# S6E1A1 register map
File version: 1.2
CPU: 
Registers are 32-bit, read-write, reset 0x0 unless marked. A register's access mark holds for its fields unless they carry their own. Offsets are from the block's base; [hi:lo] are bit positions; {n}, {i} and the like mark numbered series.

## LSCRP — Low-speed CR Prescaler Register
Base 0x4003C000
0x00 LCR_PRSLD 8-bit — Low-speed CR Prescaler Control Register
  [5:0] LCR_PRSLD — Low-speed CR Prescaler Load

## DMAC — DMAC Registers
Base 0x40060000
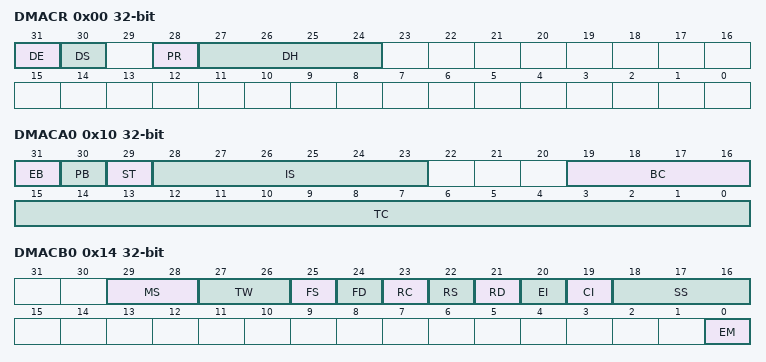
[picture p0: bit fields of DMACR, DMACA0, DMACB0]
0x00 DMACR — Entire DMAC Configuration Register
  [31] DE — DMA Enable (all-channel operation enable bit)
  [30] DS — DMA Stop
  [28] PR — Priority Rotation
  [27:24] DH — DMA Halt (All-channel pause bit)
0x10 DMACA0 — Configuration A Register
  [31] EB — Enable bit (individual-channel operation enable bit)
  [30] PB — Pause bit (individual-channel pause bit)
  [29] ST — Software Trigger
  [28:23] IS — Input Select
  [19:16] BC — Block Count
  [15:0] TC — Transfer Count
0x14 DMACB0 — Configuration B Register
  [29:28] MS — Mode Select
  [27:26] TW — Transfer Width
  [25] FS — Fixed Source
  [24] FD — Fixed Destination
  [23] RC — Reload Count (BC/TC reload)
  [22] RS — Reload Source
  [21] RD — Reload Destination
  [20] EI — Error Interrupt (unsuccessful transfer completion interrupt enable)
  [19] CI — Completion Interrupt (successful transfer completion interrupt enable)
  [18:16] SS — Stop Status (stop status notification)
  [0] EM — Enable bit Mask (EB bit clear mask)
0x18 DMACSA0 — Transfer Source Address Register 0
0x1C DMACDA0 — Transfer Destination Address Register 0
{0x10+0x10*i} DMACA{i} reset not defined (i=1..7) — Configuration A Register {i}
{0x14+0x10*i} DMACB{i} reset not defined (i=1..7) — Configuration B Register {i}
{0x18+0x10*i} DMACSA{i} reset not defined (i=1..7) — Transfer Source Address Register {i}
{0x1C+0x10*i} DMACDA{i} reset not defined (i=1..7) — Transfer Destination Address Register {i}

## MTB_DWT — Micro Trace Buffer Data Watchpoint and Trace Registers
Base 0xF0001000
0x00 CMP_ADDR_START — MTB_DWT Address Compare Start trace Register
  [31:0] ADCMP_STA — MTB_DWT address comparison start trace bits
0x04 CMP_DATA_START — MTB_DWT Data Compare Start trace Register
  [31:0] DTCMP_STA — MTB_DWT data comparison start trace bits
0x08 CMP_MASK_START — MTB_DWT Mask Data Compare Start Trace Register
  [31:0] MSK_STA — MTB_DWT data compare start trace register mask bits
0x10 CMP_ADDR_STOP — MTB_DWT Address Compare Stop trace Register
  [31:0] ADCMP_STO — MTB_DWT address comparison stop trace bits
0x14 CMP_DATA_STOP — MTB_DWT Data Compare Stop trace Register
  [31:0] DTCMP_STO — MTB_DWT data comparison stop trace bits
0x18 CMP_MASK_STOP — MTB_DWT Mask Data Compare Stop Trace Register
  [31:0] MSK_STO — MTB_DWT data compare stop trace register mask bits
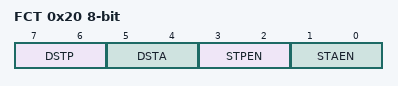
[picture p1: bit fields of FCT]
0x20 FCT 8-bit — MTB_DWT Function Register
  [7:6] DSTP — Data size stop bits
  [5:4] DSTA — Data size start bits
  [3:2] STPEN — Enable MTB_DWT stop MTB function bits
  [1:0] STAEN — Enable MTB_DWT start MTB function bits
{0xFC0+4i} PID{i} ro (i=4..7) — Peripheral ID{i} Register
  [31:0] PERID — Peripheral ID bits
0xFE0 PID0 ro reset 0x16 — Peripheral ID0 Register
  [31:0] PERID — Peripheral ID bits
0xFE4 PID1 ro reset 0x48 — Peripheral ID1 Register
  [31:0] PERID — Peripheral ID bits
0xFE8 PID2 ro reset 0x8 — Peripheral ID2 Register
  [31:0] PERID — Peripheral ID bits
0xFEC PID3 ro — Peripheral ID3 Register
  [31:0] PERID — Peripheral ID bits
0xFF0 CID0 ro reset 0xD — Component ID0 Register
  [31:0] CPNTID — Component ID bits
0xFF4 CID1 ro reset 0x90 — Component ID1 Register
  [31:0] CPNTID — Component ID bits
0xFF8 CID2 ro reset 0x5 — Component ID2 Register
  [31:0] CPNTID — Component ID bits
0xFFC CID3 ro reset 0xB1 — Component ID3 Register
  [31:0] CPNTID — Component ID bits

## FASTIO — Fast GPIO Registers
Base 0xF8000000
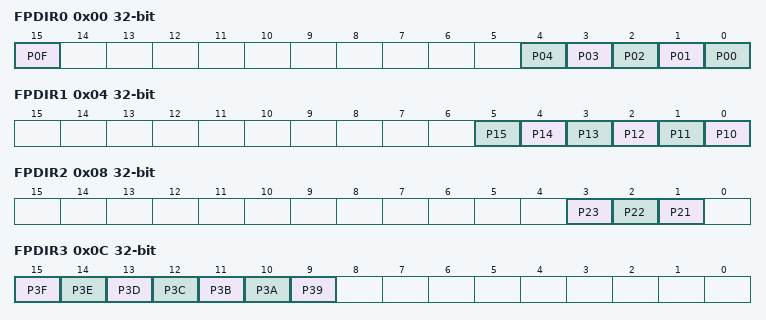
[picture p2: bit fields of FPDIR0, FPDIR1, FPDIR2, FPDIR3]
0x00 FPDIR0 ro — Fast GPIO Input Data Register 0
  [15] P0F — Bit15 of FPDIR0
  [n] P{n:02} (n=0..4) — Bit{n} of FPDIR0
0x04 FPDIR1 ro — Fast GPIO Input Data Register 1
  [n-10] P{n} (n=10..15) — Bit{n-10} of FPDIR1
0x08 FPDIR2 ro — Fast GPIO Input Data Register 2
  [3] P23 — Bit3 of FPDIR2
  [2] P22 — Bit2 of FPDIR2
  [1] P21 — Bit1 of FPDIR2
0x0C FPDIR3 ro — Fast GPIO Input Data Register 3
  [15] P3F — Bit15 of FPDIR3
  [14] P3E — Bit14 of FPDIR3
  [13] P3D — Bit13 of FPDIR3
  [12] P3C — Bit12 of FPDIR3
  [11] P3B — Bit11 of FPDIR3
  [10] P3A — Bit10 of FPDIR3
  [9] P39 — Bit9 of FPDIR3
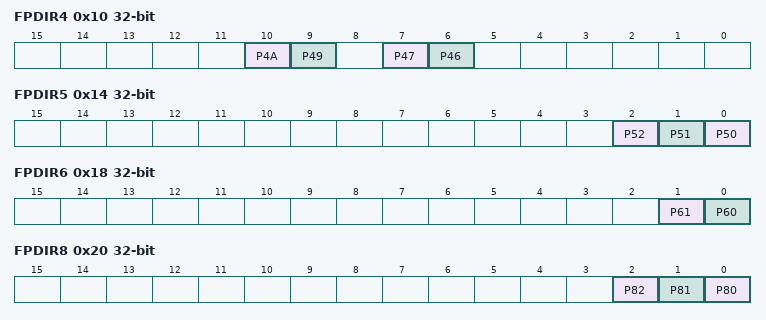
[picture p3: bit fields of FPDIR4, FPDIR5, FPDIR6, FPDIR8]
0x10 FPDIR4 ro — Fast GPIO Input Data Register 4
  [10] P4A — Bit10 of FPDIR4
  [9] P49 — Bit9 of FPDIR4
  [7] P47 — Bit7 of FPDIR4
  [6] P46 — Bit6 of FPDIR4
0x14 FPDIR5 ro — Fast GPIO Input Data Register 5
  [2] P52 — Bit2 of FPDIR5
  [1] P51 — Bit1 of FPDIR5
  [0] P50 — Bit0 of FPDIR5
0x18 FPDIR6 ro — Fast GPIO Input Data Register 6
  [1] P61 — Bit1 of FPDIR6
  [0] P60 — Bit0 of FPDIR6
0x20 FPDIR8 ro — Fast GPIO Input Data Register 8
  [2] P82 — Bit2 of FPDIR8
  [1] P81 — Bit1 of FPDIR8
  [0] P80 — Bit0 of FPDIR8
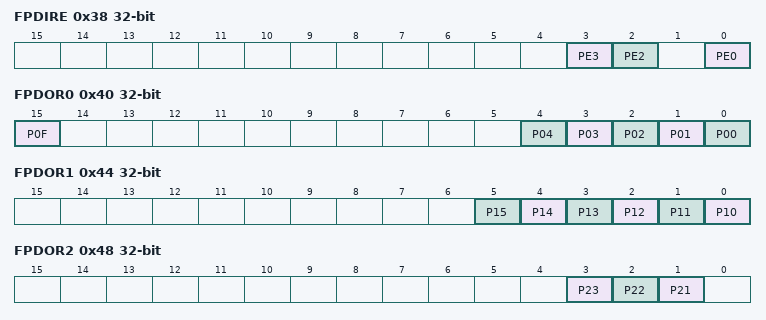
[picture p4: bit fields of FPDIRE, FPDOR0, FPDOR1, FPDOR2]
0x38 FPDIRE ro — Fast GPIO Input Data Register E
  [3] PE3 — Bit3 of FPDIRE
  [2] PE2 — Bit2 of FPDIRE
  [0] PE0 — Bit0 of FPDIRE
0x40 FPDOR0 — Fast GPIO Output Data Register 0
  [15] P0F — Bit15 of FPDOR0
  [n] P{n:02} (n=0..4) — Bit{n} of FPDOR0
0x44 FPDOR1 — Fast GPIO Output Data Register 1
  [n-10] P{n} (n=10..15) — Bit{n-10} of FPDOR1
0x48 FPDOR2 — Fast GPIO Output Data Register 2
  [3] P23 — Bit3 of FPDOR2
  [2] P22 — Bit2 of FPDOR2
  [1] P21 — Bit1 of FPDOR2
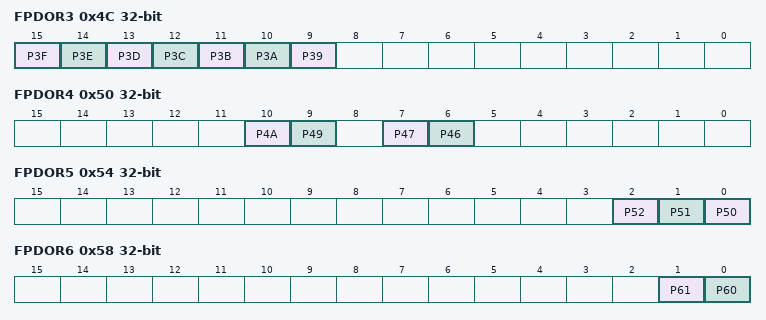
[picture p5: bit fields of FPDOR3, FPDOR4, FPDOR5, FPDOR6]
0x4C FPDOR3 — Fast GPIO Output Data Register 3
  [15] P3F — Bit15 of FPDOR3
  [14] P3E — Bit14 of FPDOR3
  [13] P3D — Bit13 of FPDOR3
  [12] P3C — Bit12 of FPDOR3
  [11] P3B — Bit11 of FPDOR3
  [10] P3A — Bit10 of FPDOR3
  [9] P39 — Bit9 of FPDOR3
0x50 FPDOR4 — Fast GPIO Output Data Register 4
  [10] P4A — Bit10 of FPDOR4
  [9] P49 — Bit9 of FPDOR4
  [7] P47 — Bit7 of FPDOR4
  [6] P46 — Bit6 of FPDOR4
0x54 FPDOR5 — Fast GPIO Output Data Register 5
  [2] P52 — Bit2 of FPDOR5
  [1] P51 — Bit1 of FPDOR5
  [0] P50 — Bit0 of FPDOR5
0x58 FPDOR6 — Fast GPIO Output Data Register 6
  [1] P61 — Bit1 of FPDOR6
  [0] P60 — Bit0 of FPDOR6
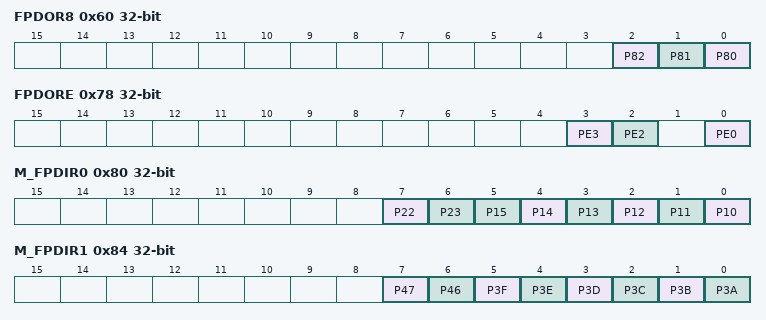
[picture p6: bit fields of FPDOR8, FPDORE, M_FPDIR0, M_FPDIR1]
0x60 FPDOR8 — Fast GPIO Output Data Register 8
  [2] P82 — Bit2 of FPDOR8
  [1] P81 — Bit1 of FPDOR8
  [0] P80 — Bit0 of FPDOR8
0x78 FPDORE — Fast GPIO Output Data Register E
  [3] PE3 — Bit3 of FPDORE
  [2] PE2 — Bit2 of FPDORE
  [0] PE0 — Bit0 of FPDORE
0x80 M_FPDIR0 ro — Mirror Fast GPIO Input Data Register 0
  [7] P22 — Bit7 of M_FPDIR0
  [6] P23 — Bit6 of M_FPDIR0
  [n-10] P{n} (n=10..15) — Bit{n-10} of M_FPDIR0
0x84 M_FPDIR1 ro — Mirror Fast GPIO Input Data Register 1
  [7] P47 — Bit7 of M_FPDIR1
  [6] P46 — Bit6 of M_FPDIR1
  [5] P3F — Bit5 of M_FPDIR1
  [4] P3E — Bit4 of M_FPDIR1
  [3] P3D — Bit3 of M_FPDIR1
  [2] P3C — Bit2 of M_FPDIR1
  [1] P3B — Bit1 of M_FPDIR1
  [0] P3A — Bit0 of M_FPDIR1
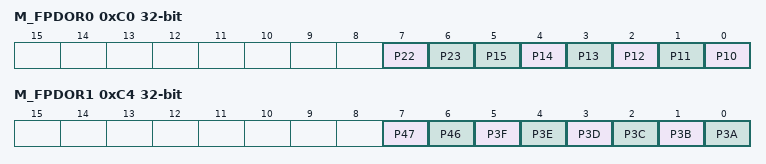
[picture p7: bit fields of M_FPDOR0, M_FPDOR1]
0xC0 M_FPDOR0 — Mirror Fast GPIO Output Data Register 0
  [7] P22 — Bit7 of M_FPDOR0
  [6] P23 — Bit6 of M_FPDOR0
  [n-10] P{n} (n=10..15) — Bit{n-10} of M_FPDOR0
0xC4 M_FPDOR1 — Mirror Fast GPIO Output Data Register 1
  [7] P47 — Bit7 of M_FPDOR1
  [6] P46 — Bit6 of M_FPDOR1
  [5] P3F — Bit5 of M_FPDOR1
  [4] P3E — Bit4 of M_FPDOR1
  [3] P3D — Bit3 of M_FPDOR1
  [2] P3C — Bit2 of M_FPDOR1
  [1] P3B — Bit1 of M_FPDOR1
  [0] P3A — Bit0 of M_FPDOR1
